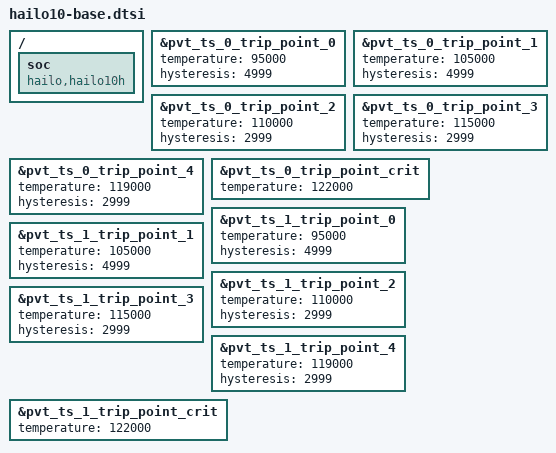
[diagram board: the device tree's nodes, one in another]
// SPDX-License-Identifier:     GPL-2.0
/*
 * Copyright (c) 2019-2024 Hailo Technologies Ltd. All rights reserved.
 */

#include "hailo15-base.dtsi"

/ {
    soc {
        compatible = "hailo,hailo10h";
    };
};

&pvt_ts_0_trip_point_0 {
    temperature = <95000>;
    hysteresis = <4999>;
};
&pvt_ts_0_trip_point_1 {
    temperature = <105000>;
    hysteresis = <4999>;
};
&pvt_ts_0_trip_point_2 {
    temperature = <110000>;
    hysteresis = <2999>;
};
&pvt_ts_0_trip_point_3 {
    temperature = <115000>;
    hysteresis = <2999>;
};
&pvt_ts_0_trip_point_4 {
    temperature = <119000>;
    hysteresis = <2999>;
};
&pvt_ts_0_trip_point_crit {
    temperature = <122000>;
};

&pvt_ts_1_trip_point_0 {
    temperature = <95000>;
    hysteresis = <4999>;
};
&pvt_ts_1_trip_point_1 {
    temperature = <105000>;
    hysteresis = <4999>;
};
&pvt_ts_1_trip_point_2 {
    temperature = <110000>;
    hysteresis = <2999>;
};
&pvt_ts_1_trip_point_3 {
    temperature = <115000>;
    hysteresis = <2999>;
};
&pvt_ts_1_trip_point_4 {
    temperature = <119000>;
    hysteresis = <2999>;
};
&pvt_ts_1_trip_point_crit {
    temperature = <122000>;
};
